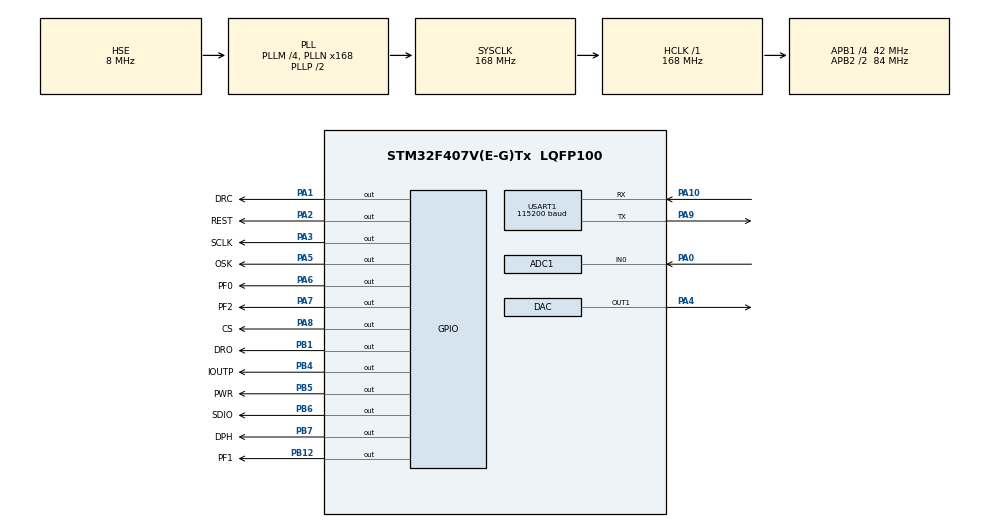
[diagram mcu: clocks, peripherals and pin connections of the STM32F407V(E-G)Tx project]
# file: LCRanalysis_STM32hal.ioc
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ADC1.Channel-0\#ChannelRegularConversion=ADC_CHANNEL_0
ADC1.ContinuousConvMode=ENABLE
ADC1.DMAContinuousRequests=ENABLE
ADC1.NbrOfConversion=1
ADC1.NbrOfConversionFlag=1
ADC1.Rank-0\#ChannelRegularConversion=1
ADC1.SamplingTime-0\#ChannelRegularConversion=ADC_SAMPLETIME_3CYCLES
ADC1.ScanConvMode=ENABLE
ADC1.master=1
DAC.DAC_OutputBuffer=DAC_OUTPUTBUFFER_ENABLE
Dma.ADC1.0.Direction=DMA_PERIPH_TO_MEMORY
Dma.ADC1.0.FIFOMode=DMA_FIFOMODE_DISABLE
Dma.ADC1.0.Instance=DMA2_Stream0
Dma.ADC1.0.MemDataAlignment=DMA_MDATAALIGN_HALFWORD
Dma.ADC1.0.MemInc=DMA_MINC_ENABLE
Dma.ADC1.0.Mode=DMA_CIRCULAR
Dma.ADC1.0.PeriphDataAlignment=DMA_PDATAALIGN_HALFWORD
Dma.ADC1.0.PeriphInc=DMA_PINC_DISABLE
Dma.ADC1.0.Priority=DMA_PRIORITY_LOW
Dma.Request0=ADC1
Mcu.Family=STM32F4
Mcu.Name=STM32F407V(E-G)Tx
Mcu.Package=LQFP100
NVIC.DMA2_Stream0_IRQn=true\:0\:0\:false\:false\:true\:false\:true\:true
NVIC.PriorityGroup=NVIC_PRIORITYGROUP_4
PA0-WKUP.Signal=ADCx_IN0
PA1.GPIO_Label=DRC
PA1.GPIO_Speed=GPIO_SPEED_FREQ_VERY_HIGH
PA1.Signal=GPIO_Output
PA10.Mode=Asynchronous
PA10.Signal=USART1_RX
PA13.Mode=Serial_Wire
PA13.Signal=SYS_JTMS-SWDIO
PA14.Mode=Serial_Wire
PA14.Signal=SYS_JTCK-SWCLK
PA2.GPIO_Label=REST
PA2.GPIO_Speed=GPIO_SPEED_FREQ_VERY_HIGH
PA2.PinState=GPIO_PIN_SET
PA2.Signal=GPIO_Output
PA3.GPIO_Label=SCLK
PA3.GPIO_Speed=GPIO_SPEED_FREQ_VERY_HIGH
PA3.PinState=GPIO_PIN_SET
PA3.Signal=GPIO_Output
PA4.Signal=COMP_DAC1_group
PA5.GPIO_Label=OSK
PA5.GPIO_Speed=GPIO_SPEED_FREQ_VERY_HIGH
PA5.PinState=GPIO_PIN_SET
PA5.Signal=GPIO_Output
PA6.GPIO_Label=PF0
PA6.GPIO_Speed=GPIO_SPEED_FREQ_VERY_HIGH
PA6.PinState=GPIO_PIN_SET
PA6.Signal=GPIO_Output
PA7.GPIO_Label=PF2
PA7.GPIO_Speed=GPIO_SPEED_FREQ_VERY_HIGH
PA7.PinState=GPIO_PIN_SET
PA7.Signal=GPIO_Output
PA8.GPIO_Label=CS
PA8.GPIO_Speed=GPIO_SPEED_FREQ_VERY_HIGH
PA8.PinState=GPIO_PIN_SET
PA8.Signal=GPIO_Output
PA9.Mode=Asynchronous
PA9.Signal=USART1_TX
PB1.GPIO_Label=DRO
PB1.GPIO_Speed=GPIO_SPEED_FREQ_VERY_HIGH
PB1.PinState=GPIO_PIN_SET
PB1.Signal=GPIO_Output
PB12.GPIO_Label=PF1
PB12.GPIO_Speed=GPIO_SPEED_FREQ_VERY_HIGH
PB12.PinState=GPIO_PIN_SET
PB12.Signal=GPIO_Output
PB4.GPIO_Label=IOUTP
PB4.GPIO_Speed=GPIO_SPEED_FREQ_VERY_HIGH
PB4.Signal=GPIO_Output
PB5.GPIO_Label=PWR
PB5.GPIO_ModeDefaultOutputPP=GPIO_MODE_OUTPUT_PP
PB5.GPIO_Speed=GPIO_SPEED_FREQ_VERY_HIGH
PB5.PinState=GPIO_PIN_SET
PB5.Signal=GPIO_Output
PB6.GPIO_Label=SDIO
PB6.GPIO_Speed=GPIO_SPEED_FREQ_VERY_HIGH
PB6.PinState=GPIO_PIN_SET
PB6.Signal=GPIO_Output
PB7.GPIO_Label=DPH
PB7.GPIO_Speed=GPIO_SPEED_FREQ_VERY_HIGH
PB7.PinState=GPIO_PIN_SET
PB7.Signal=GPIO_Output
PH0-OSC_IN.Mode=HSE-External-Oscillator
PH0-OSC_IN.Signal=RCC_OSC_IN
PH1-OSC_OUT.Mode=HSE-External-Oscillator
PH1-OSC_OUT.Signal=RCC_OSC_OUT
ProjectManager.HeapSize=0x200
ProjectManager.StackSize=0x400
ProjectManager.TargetToolchain=CMake
RCC.48MHZClocksFreq_Value=84000000
RCC.AHBFreq_Value=168000000
RCC.APB1CLKDivider=RCC_HCLK_DIV4
RCC.APB1Freq_Value=42000000
RCC.APB1TimFreq_Value=84000000
RCC.APB2CLKDivider=RCC_HCLK_DIV2
RCC.APB2Freq_Value=84000000
RCC.APB2TimFreq_Value=168000000
RCC.CortexFreq_Value=168000000
RCC.FLatency=FLASH_LATENCY_5
RCC.HCLKFreq_Value=168000000
RCC.HSE_VALUE=8000000
RCC.HSI_VALUE=16000000
RCC.LSE_VALUE=32768
RCC.PLLM=4
RCC.PLLN=168
RCC.PLLSourceVirtual=RCC_PLLSOURCE_HSE
RCC.SYSCLKFreq_VALUE=168000000
RCC.SYSCLKSource=RCC_SYSCLKSOURCE_PLLCLK
RCC.VCOOutputFreq_Value=336000000
SH.ADCx_IN0.0=ADC1_IN0,IN0
SH.COMP_DAC1_group.0=DAC_OUT1,DAC_OUT1
STMicroelectronics.X-CUBE-ALGOBUILD.1.4.0.LibraryCcDSPOoLibraryJjDSPOoLibrary=true
USART1.BaudRate=115200
USART1.Mode=MODE_TX_RX
USART1.OverSampling=UART_OVERSAMPLING_16
USART1.Parity=PARITY_NONE
USART1.StopBits=STOPBITS_1
USART1.VirtualMode=VM_ASYNC
USART1.WordLength=WORDLENGTH_8B
VP_STMicroelectronics.X-CUBE-ALGOBUILD_VS_DSPOoLibraryJjLibrary_1.4.0_1.4.0.Mode=DSPOoLibraryJjLibrary
board=custom

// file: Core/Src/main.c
/* USER CODE BEGIN Header */
/**
  ******************************************************************************
  * @file           : main.c
  * @brief          : Main program body
  ******************************************************************************
  * @attention
  *
  * Copyright (c) 2025 STMicroelectronics.
  * All rights reserved.
  *
  * This software is licensed under terms that can be found in the LICENSE file
  * in the root directory of this software component.
  * If no LICENSE file comes with this software, it is provided AS-IS.
  *
  ******************************************************************************
  */
/* USER CODE END Header */
#include "main.h"
#include "adc.h"
#include "dac.h"
#include "dma.h"
#include "usart.h"
#include "gpio.h"

/* USER CODE BEGIN Includes */

#include "FFT.h"
#include "AD9910.h"
#include "PGA.h"
#include "gainDetermination.h"

/* USER CODE END Includes */

/* USER CODE BEGIN PV */
uint16_t chipADCbuf[FFT_LENGTH] = {0}; // Buffer for ADC data, size 256
unsigned long freq = 100;
uint16_t amplitude = 1500;
/* USER CODE END PV */

void SystemClock_Config(void);

int main(void)
{

  /* MCU Configuration--------------------------------------------------------*/

  /* Reset of all peripherals, Initializes the Flash interface and the Systick. */
  HAL_Init();

  /* Configure the system clock */
  SystemClock_Config();

  /* Initialize all configured peripherals */
  MX_GPIO_Init();
  MX_DMA_Init();
  MX_ADC1_Init();
  MX_USART1_UART_Init();
  MX_DAC_Init();
  /* USER CODE BEGIN 2 */
  HAL_ADC_Start_DMA(&hadc1, (uint32_t *)chipADCbuf, FFT_LENGTH);

  Init_ad9910();
  //单频调制模式*/
  // Freq_convert(100);   //设置频率为1k,正弦波
  // Write_Amplitude(800); //设置幅值（1-800mV）幅度设置为粗略设置
  /* USER CODE END 2 */

  /* Infinite loop */
  /* USER CODE BEGIN WHILE */
  while (1)
  {
    // knownModelOutputSet(amplitude, freq);
    Freq_convert(2000000);   //设置频率为1k,正弦波
    Write_Amplitude(50); //设置幅值（1-800mV）幅度设置为粗略设置
    HAL_Delay(500);
    /* USER CODE END WHILE */

  }
}

void SystemClock_Config(void)
{
  RCC_OscInitTypeDef RCC_OscInitStruct = {0};
  RCC_ClkInitTypeDef RCC_ClkInitStruct = {0};

  /** Configure the main internal regulator output voltage
  */
  __HAL_RCC_PWR_CLK_ENABLE();
  __HAL_PWR_VOLTAGESCALING_CONFIG(PWR_REGULATOR_VOLTAGE_SCALE1);

  /** Initializes the RCC Oscillators according to the specified parameters
  * in the RCC_OscInitTypeDef structure.
  */
  RCC_OscInitStruct.OscillatorType = RCC_OSCILLATORTYPE_HSE;
  RCC_OscInitStruct.HSEState = RCC_HSE_ON;
  RCC_OscInitStruct.PLL.PLLState = RCC_PLL_ON;
  RCC_OscInitStruct.PLL.PLLSource = RCC_PLLSOURCE_HSE;
  RCC_OscInitStruct.PLL.PLLM = 4;
  RCC_OscInitStruct.PLL.PLLN = 168;
  RCC_OscInitStruct.PLL.PLLP = RCC_PLLP_DIV2;
  RCC_OscInitStruct.PLL.PLLQ = 4;
  if (HAL_RCC_OscConfig(&RCC_OscInitStruct) != HAL_OK)
  {
    Error_Handler();
  }

  /** Initializes the CPU, AHB and APB buses clocks
  */
  RCC_ClkInitStruct.ClockType = RCC_CLOCKTYPE_HCLK|RCC_CLOCKTYPE_SYSCLK
                              |RCC_CLOCKTYPE_PCLK1|RCC_CLOCKTYPE_PCLK2;
  RCC_ClkInitStruct.SYSCLKSource = RCC_SYSCLKSOURCE_PLLCLK;
  RCC_ClkInitStruct.AHBCLKDivider = RCC_SYSCLK_DIV1;
  RCC_ClkInitStruct.APB1CLKDivider = RCC_HCLK_DIV4;
  RCC_ClkInitStruct.APB2CLKDivider = RCC_HCLK_DIV2;

  if (HAL_RCC_ClockConfig(&RCC_ClkInitStruct, FLASH_LATENCY_5) != HAL_OK)
  {
    Error_Handler();
  }
}

void Error_Handler(void)
{
  __disable_irq();
  while (1)
  {
  }
}
